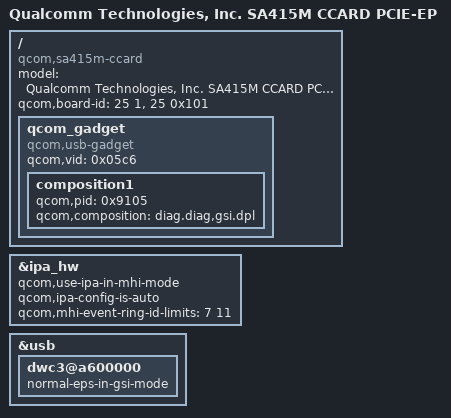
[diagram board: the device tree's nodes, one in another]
/dts-v1/;

#include "sa415m-ccard.dtsi"

/ {
	model = "Qualcomm Technologies, Inc. SA415M CCARD PCIE-EP";
	compatible = "qcom,sa415m-ccard",
			"qcom,sa415m", "qcom,ccard";
	qcom,board-id = <25 1>, <25 0x101>;

	qcom_gadget {
		compatible = "qcom,usb-gadget";
		qcom,vid = <0x05c6>;

		composition1 {
			qcom,pid = <0x9105>;
			qcom,composition = "diag.diag,gsi.dpl";
		};
	};

};

&ipa_hw {
	qcom,use-ipa-in-mhi-mode;
	qcom,ipa-config-is-auto;
	qcom,mhi-event-ring-id-limits = <7 11>; /* start and end */
};

&usb {
	dwc3@a600000 {
		normal-eps-in-gsi-mode;
	};
};
